# ecd5_target_db register map
Vendor: Texas Instruments
Address unit: 16 bits
Registers are 32-bit, access per field, reset 0x0 unless marked. A register's access mark holds for its fields unless they carry their own. Offsets are as the file gives them; [hi:lo] are bit positions; {n}, {i} and the like mark numbered series; 'fields as' and 'values as' point back to an identical list; <NAME> marks a mode.

## DSS (part 2 of 5) — ipxact12_to_ccs_generated
{0x4C+8i} __ALL___DRM_BUF_DMAGROUPID_BIN{i} (i=1..3) — DMA Group ID for bin stream {i} Note : Valid only in frame decoupled mode
  [5:0] ID rw — Group ID for VDMA transfer
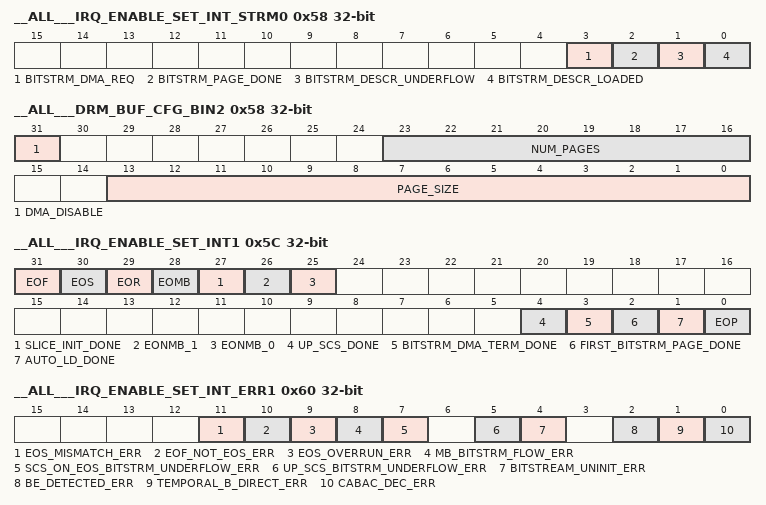
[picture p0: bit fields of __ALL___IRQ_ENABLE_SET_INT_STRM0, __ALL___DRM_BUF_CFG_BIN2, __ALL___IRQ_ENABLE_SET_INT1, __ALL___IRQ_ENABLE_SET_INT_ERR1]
0x58 __ALL___IRQ_ENABLE_SET_INT_STRM0 — Interrupt enable for each of the sources for interrupt INT_STRM0 Writing "1" to specific field in this register enables the corresponding source for interrupt generatation The read value reflects whether the corresponding source is enabled/disabled for interrupt generation The following is the behavior for read/write into each of the individual fields : Write 0: No action Write 1: Enable interrupt Read 0: Interrupt disabled (masked) Read 1: Interrupt enabled
  [3] BITSTRM_DMA_REQ rw — S/W interactive DMA request interrupt enable
  [2] BITSTRM_PAGE_DONE rw — Page of Bitstream DMA done interrupt enable.
  [1] BITSTRM_DESCR_UNDERFLOW rw — DDR/SL2 bitstream data descriptor underflow interrupt enable
  [0] BITSTRM_DESCR_LOADED rw — DDR/SL2 bitstream data descriptor loaded interrupt enable
0x58 __ALL___DRM_BUF_CFG_BIN2 — Buffer Parameters and configuration for bin stream 2 Note : Valid only in frame decoupled mode
  [31] DMA_DISABLE rw — If '1', disables the triggering of VDMA. Only the SL2 buffer management is activated.
  [23:16] NUM_PAGES rw — Number of pages in SL2
  [13:0] PAGE_SIZE rw — Size of each page in SL2 (in bytes); bits[3:0] are ignored, so the effective size is a multiple of 16 bytes Although the VDMA transfer for bin stream is deterministic, PAGE_SIZE is needed by ECD5 to know when to trigger VDMA - i.e. when the page becomes full. Since the size of each entry/write in the bin buffer is not fixed, the DMA is triggered when the total size of the wriiten data reaches PAGE_SIZE
0x5C __ALL___IRQ_ENABLE_SET_INT1 — Interrupt enable for each of the sources for interrupt INT1 Writing "1" to specific field in this register enables the corresponding source for interrupt generatation The read value reflects whether the corresponding source is enabled/disabled for interrupt generation The following is the behavior for read/write into each of the individual fields : Write 0: No action Write 1: Enable interrupt Read 0: Interrupt disabled (masked) Read 1: Interrupt enabled
  [31] EOF rw — End of Frame Interrupt enable
  [30] EOS rw — End of Slice Interrupt enable
  [29] EOR rw — End of Row Interrupt enable
  [28] EOMB rw — End of Macroblock Interrupt enable
  [27] SLICE_INIT_DONE rw — Slice init done interrupt enable
  [26] EONMB_1 rw — End of N Macroblock (i.e. counter 1 expired) interrupt enable.
  [25] EONMB_0 rw — End of N Macroblock (i.e. counter 0 expired) interrupt enable
  [4] UP_SCS_DONE rw — Unit processing startcode search interrupt enable.
  [3] BITSTRM_DMA_TERM_DONE rw — Bitstream DMA termination completed interrupt enable.
  [2] FIRST_BITSTRM_PAGE_DONE rw — First bitstream page DMA done interrupt enable
  [1] AUTO_LD_DONE rw — Auto Load Done Interrupt Enable
  [0] EOP rw — End of Pipe Interrupt enable
0x60 __ALL___IRQ_ENABLE_SET_INT_ERR1 — Interrupt enable for each of the sources for interrupt INT_ERR1 Writing "1" to specific field in this register enables the corresponding source for interrupt generatation The read value reflects whether the corresponding source is enabled/disabled for interrupt generation The following is the behavior for read/write into each of the individual fields : Write 0: No action Write 1: Enable interrupt Read 0: Interrupt disabled (masked) Read 1: Interrupt enabled
  [11] EOS_MISMATCH_ERR rw — End of slice mismatch error interrupt enable.
  [10] EOF_NOT_EOS_ERR rw — End of frame is not end of slice error interrupt enable
  [9] EOS_OVERRUN_ERR rw — End of slice overrun error interrupt enable
  [8] MB_BITSTRM_FLOW_ERR rw — Underflow in bitstream during MB decode error interrupt enable.
  [7] SCS_ON_EOS_BITSTRM_UNDERFLOW_ERR rw — Underflow in bitstream during startcode search after EOS error interrupt enable.
  [5] UP_SCS_BITSTRM_UNDERFLOW_ERR rw — Underflow in bitstream during startcode search unit processing.
  [4] BITSTREAM_UNINIT_ERR rw — Bitstream initialization without bitstream descriptor programmation error interrupt enable
  [2] BE_DETECTED_ERR rw — FE error due to error detected in BE interrupt enable.
  [1] TEMPORAL_B_DIRECT_ERR rw — Temporal B Direct Detected Error Interrupt Enable
  [0] CABAC_DEC_ERR rw — CABAC Decoder Error Interrupt Enable
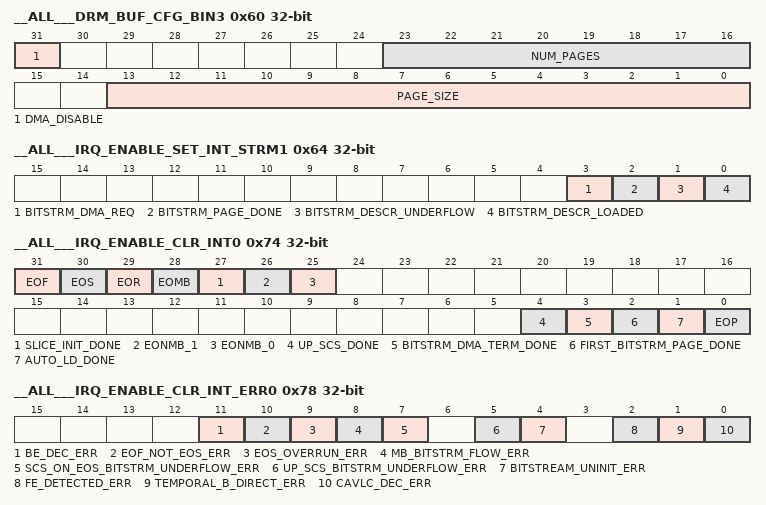
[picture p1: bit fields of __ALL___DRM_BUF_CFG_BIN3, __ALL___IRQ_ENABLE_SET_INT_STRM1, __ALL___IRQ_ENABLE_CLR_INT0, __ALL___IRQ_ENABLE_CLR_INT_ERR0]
0x60 __ALL___DRM_BUF_CFG_BIN3 — Buffer Parameters and configuration for bin stream 3 Note : Valid only in frame decoupled mode
  fields as __ALL___DRM_BUF_CFG_BIN2
0x64 __ALL___IRQ_ENABLE_SET_INT_STRM1 — Interrupt enable for each of the sources for interrupt INT_STRM1 Writing "1" to specific field in this register enables the corresponding source for interrupt generatation The read value reflects whether the corresponding source is enabled/disabled for interrupt generation The following is the behavior for read/write into each of the individual fields : Write 0: No action Write 1: Enable interrupt Read 0: Interrupt disabled (masked) Read 1: Interrupt enabled
  fields as __ALL___IRQ_ENABLE_SET_INT_STRM0
0x74 __ALL___IRQ_ENABLE_CLR_INT0 — Interrupt disable for each of the sources for interrupt INT0 Writing "1" to specific field in this register disables the corresponding source for interrupt generatation The read value reflects whether the corresponding source is enabled/disabled for interrupt generation The following is the behavior for read/write into each of the individual fields : Write 0: No action Write 1: Disable interrupt Read 0: Interrupt disabled (masked) Read 1: Interrupt enabled
  [31] EOF rw — End of Frame Interrupt disable
  [30] EOS rw — End of Slice Interrupt disable
  [29] EOR rw — End of Row Interrupt disable
  [28] EOMB rw — End of Macroblock Interrupt disable
  [27] SLICE_INIT_DONE rw — Slice init done interrupt disable
  [26] EONMB_1 rw — End of N Macroblock (i.e. counter 1 expired) interrupt disable
  [25] EONMB_0 rw — End of N Macroblock (i.e. counter 0 expired) interrupt disable
  [4] UP_SCS_DONE rw — Unit processing startcode search interrupt disable
  [3] BITSTRM_DMA_TERM_DONE rw — Bitstream DMA termination completed interrupt disable.
  [2] FIRST_BITSTRM_PAGE_DONE rw — First bitstream page DMA done interrupt disable
  [1] AUTO_LD_DONE rw — Auto Load Done Interrupt disable
  [0] EOP rw — End of Pipe Interrupt disable
0x78 __ALL___IRQ_ENABLE_CLR_INT_ERR0 — Interrupt disable for each of the sources for interrupt INT_ERR0 Writing "1" to specific field in this register disables the corresponding source for interrupt generatation The read value reflects whether the corresponding source is enabled/disabled for interrupt generation The following is the behavior for read/write into each of the individual fields : Write 0: No action Write 1: Disable interrupt Read 0: Interrupt disabled (masked) Read 1: Interrupt enabled
  [11] BE_DEC_ERR rw — BE Decoder Error interrupt disable
  [10] EOF_NOT_EOS_ERR rw — End of frame is not end of slice error interrupt disable
  [9] EOS_OVERRUN_ERR rw — End of slice overrun error interrupt disable
  [8] MB_BITSTRM_FLOW_ERR rw — Underflow/overflow in bitstream during MB decode/encode error interrupt disable.
  [7] SCS_ON_EOS_BITSTRM_UNDERFLOW_ERR rw — Underflow in bitstream during startcode search after EOS error interrupt disable.
  [5] UP_SCS_BITSTRM_UNDERFLOW_ERR rw — Underflow in bitstream during startcode search unit processing
  [4] BITSTREAM_UNINIT_ERR rw — Bitstream initialization without bitstream descriptor programmation error interrupt disable
  [2] FE_DETECTED_ERR rw — BE error due to error detected in FE interrupt disable.
  [1] TEMPORAL_B_DIRECT_ERR rw — Temporal B Direct Detected Error Interrupt disable
  [0] CAVLC_DEC_ERR rw — CAVLC Decoder Error Interrupt disable
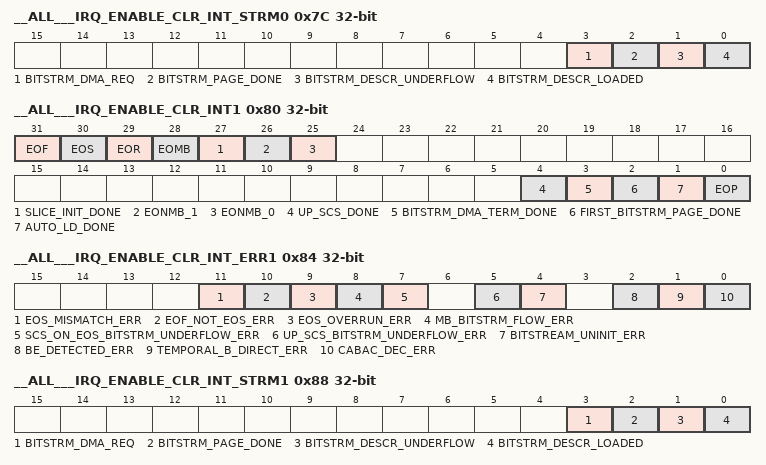
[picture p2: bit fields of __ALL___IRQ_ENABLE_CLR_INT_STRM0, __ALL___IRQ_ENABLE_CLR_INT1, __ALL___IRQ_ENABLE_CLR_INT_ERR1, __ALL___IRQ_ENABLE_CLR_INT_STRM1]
0x7C __ALL___IRQ_ENABLE_CLR_INT_STRM0 — Interrupt disable for each of the sources for interrupt INT_STRM0 Writing "1" to specific field in this register disables the corresponding source for interrupt generatation The read value reflects whether the corresponding source is enabled/disabled for interrupt generation The following is the behavior for read/write into each of the individual fields : Write 0: No action Write 1: Disable interrupt Read 0: Interrupt disabled (masked) Read 1: Interrupt enabled
  [3] BITSTRM_DMA_REQ rw — S/W interactive DMA request interrupt disable
  [2] BITSTRM_PAGE_DONE rw — Page of Bitstream DMA done interrupt disable
  [1] BITSTRM_DESCR_UNDERFLOW rw — DDR/SL2 bitstream data descriptor underflow interrupt disable
  [0] BITSTRM_DESCR_LOADED rw — DDR/SL2 bitstream data descriptor loaded interrupt disable
0x80 __ALL___IRQ_ENABLE_CLR_INT1 — Interrupt disable for each of the sources for interrupt INT1 Writing "1" to specific field in this register disables the corresponding source for interrupt generatation The read value reflects whether the corresponding source is enabled/disabled for interrupt generation The following is the behavior for read/write into each of the individual fields : Write 0: No action Write 1: Disable interrupt Read 0: Interrupt disabled (masked) Read 1: Interrupt enabled
  fields as __ALL___IRQ_ENABLE_CLR_INT0
0x84 __ALL___IRQ_ENABLE_CLR_INT_ERR1 — Interrupt disable for each of the sources for interrupt INT_ERR1 Writing "1" to specific field in this register disables the corresponding source for interrupt generatation The read value reflects whether the corresponding source is enabled/disabled for interrupt generation The following is the behavior for read/write into each of the individual fields : Write 0: No action Write 1: Disable interrupt Read 0: Interrupt disabled (masked) Read 1: Interrupt enabled
  [11] EOS_MISMATCH_ERR rw — End of slice mismatch error interrupt disable.
  [10] EOF_NOT_EOS_ERR rw — End of frame is not end of slice error interrupt disable
  [9] EOS_OVERRUN_ERR rw — End of slice overrun error interrupt enable
  [8] MB_BITSTRM_FLOW_ERR rw — Underflow in bitstream during MB decode error interrupt disable.
  [7] SCS_ON_EOS_BITSTRM_UNDERFLOW_ERR rw — Underflow in bitstream during startcode search after EOS error interrupt disable.
  [5] UP_SCS_BITSTRM_UNDERFLOW_ERR rw — Underflow in bitstream during startcode search unit processing.
  [4] BITSTREAM_UNINIT_ERR rw — Bitstream initialization without bitstream descriptor programmation error interrupt disable
  [2] BE_DETECTED_ERR rw — FE error due to error detected in BE interrupt disable.
  [1] TEMPORAL_B_DIRECT_ERR rw — Temporal B Direct Detected Error Interrupt disable
  [0] CABAC_DEC_ERR rw — CABAC Decoder Error Interrupt disable
0x88 __ALL___IRQ_ENABLE_CLR_INT_STRM1 — Interrupt disable for each of the sources for interrupt INT_STRM1 Writing "1" to specific field in this register disables the corresponding source for interrupt generatation The read value reflects whether the corresponding source is enabled/disabled for interrupt generation The following is the behavior for read/write into each of the individual fields : Write 0: No action Write 1: Disable interrupt Read 0: Interrupt disabled (masked) Read 1: Interrupt enabled
  fields as __ALL___IRQ_ENABLE_CLR_INT_STRM0
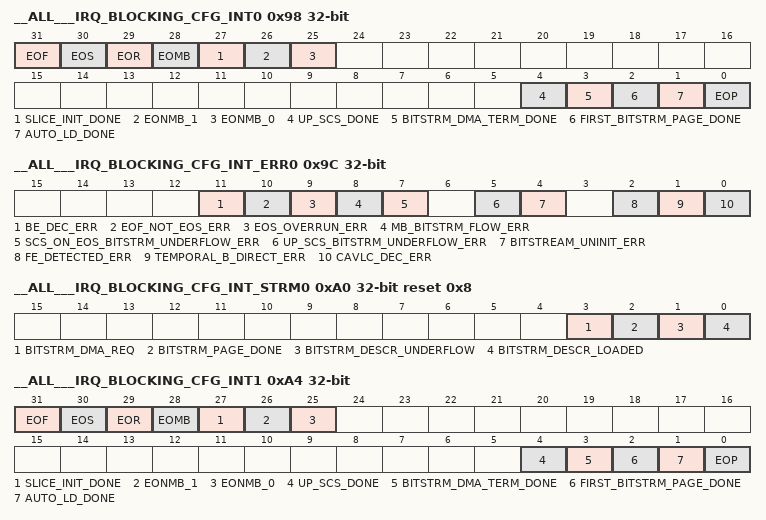
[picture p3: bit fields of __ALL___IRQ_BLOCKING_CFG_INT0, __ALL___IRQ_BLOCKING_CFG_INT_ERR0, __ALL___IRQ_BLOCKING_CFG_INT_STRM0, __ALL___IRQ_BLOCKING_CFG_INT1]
0x98 __ALL___IRQ_BLOCKING_CFG_INT0 — Interrupt blocking configuration for interrupt INT0 If a bit in this register is set to "1", the ECD5 halts after it generates an interrupt for the corresponding interrupt source, and waits for interrupt acknowledgement for that interrupt line before continuing execution. If a bit in this register is set to "0", the ECD5 does not halt after it generates an interrupt for the corresponding interrupt source The configuration in this register only apply to enabled interrupt sources Note : The halt on blocking interrupt is independent for FE and BE; i.e. if BE generates a blocking interrupt, only the BE is halted until ack is received; the FE continues processing.
  [31] EOF rw — End of Frame Interrupt blocking configuration
  [30] EOS rw — End of Slice Interrupt blocking configuration
  [29] EOR rw — End of Row Interrupt blocking configuration
  [28] EOMB rw — End of Macroblock Interrupt blocking configuration
  [27] SLICE_INIT_DONE rw — Slice init done interrupt blocking configuration
  [26] EONMB_1 rw — End of N Macroblock (i.e. counter 1 expired) interrupt blocking configuration
  [25] EONMB_0 rw — End of N Macroblock (i.e. counter 0 expired) interrupt blocking configuration
  [4] UP_SCS_DONE rw — Unit processing startcode search interrupt blocking configuration
  [3] BITSTRM_DMA_TERM_DONE rw — Bitstream DMA termination completed interrupt blocking configuration.
  [2] FIRST_BITSTRM_PAGE_DONE rw — First bitstream page DMA done interrupt blocking configuration
  [1] AUTO_LD_DONE rw — Auto Load Done Interrupt blocking configuration
  [0] EOP rw — End of Pipe Interrupt blocking configuration
0x9C __ALL___IRQ_BLOCKING_CFG_INT_ERR0 — Interrupt blocking configuration for interrupt INT_ERR0 If a bit in this register is set to "1", the ECD5 halts after it generates an interrupt for the corresponding interrupt source, and waits for interrupt acknowledgement for that interrupt line before continuing execution. If a bit in this register is set to "0", the ECD5 does not halt after it generates an interrupt for the corresponding interrupt source The configuration in this register only apply to enabled interrupt sources Note : The halt on blocking interrupt is independent for FE and BE; i.e. if BE generates a blocking interrupt, only the BE is halted until ack is received; the FE continues processing.
  [11] BE_DEC_ERR rw — BE Decoder Error interrupt blocking configuration
  [10] EOF_NOT_EOS_ERR rw — End of frame is not end of slice error interrupt blocking configuration
  [9] EOS_OVERRUN_ERR rw — End of slice overrun error interrupt blocking configuration
  [8] MB_BITSTRM_FLOW_ERR rw — Underflow/overflow in bitstream during MB decode/encode error interrupt blocking configuration.
  [7] SCS_ON_EOS_BITSTRM_UNDERFLOW_ERR rw — Underflow in bitstream during startcode search after EOS error interrupt blocking configuration.
  [5] UP_SCS_BITSTRM_UNDERFLOW_ERR rw — Underflow in bitstream during startcode search unit processing interrupt blocking configuration.
  [4] BITSTREAM_UNINIT_ERR rw — Bitstream initialization without bitstream descriptor programmation error interrupt blocking configuration.
  [2] FE_DETECTED_ERR rw — BE error due to error detected in FE interrupt blocking configuration.
  [1] TEMPORAL_B_DIRECT_ERR rw — Temporal B Direct Detected Error interrupt blocking configuration
  [0] CAVLC_DEC_ERR rw — CAVLC Decoder Error interrupt blocking configuration
0xA0 __ALL___IRQ_BLOCKING_CFG_INT_STRM0 reset 0x8 — Interrupt blocking configuration for interrupt INT_STRM0 If a bit in this register is set to "1", the ECD5 halts after it generates an interrupt for the corresponding interrupt source, and waits for interrupt acknowledgement for that interrupt line before continuing execution. If a bit in this register is set to "0", the ECD5 does not halt after it generates an interrupt for the corresponding interrupt source The configuration in this register only apply to enabled interrupt sources Note : The halt on blocking interrupt is independent for FE and BE; i.e. if BE generates a blocking interrupt, only the BE is halted until ack is received; the FE continues processing.
  [3] BITSTRM_DMA_REQ ro — S/W interactive DMA request interrupt blocking configuration. This interrupt is always blocking.
  [2] BITSTRM_PAGE_DONE rw — Page of Bitstream DMA done interrupt blocking configuration
  [1] BITSTRM_DESCR_UNDERFLOW rw — DDR/SL2 bitstream data descriptor underflow interrupt blocking configuration
  [0] BITSTRM_DESCR_LOADED rw — DDR/SL2 bitstream data descriptor loaded interrupt blocking configuration
0xA4 __ALL___IRQ_BLOCKING_CFG_INT1 — Interrupt blocking configuration for interrupt INT1 If a bit in this register is set to "1", the ECD5 halts after it generates an interrupt for the corresponding interrupt source, and waits for interrupt acknowledgement for that interrupt line before continuing execution. If a bit in this register is set to "0", the ECD5 does not halt after it generates an interrupt for the corresponding interrupt source The configuration in this register only apply to enabled interrupt sources Note : The halt on blocking interrupt is independent for FE and BE; i.e. if BE generates a blocking interrupt, only the BE is halted until ack is received; the FE continues processing.
  [31] EOF rw — End of Frame interrupt blocking configuration
  [30] EOS rw — End of Slice interrupt blocking configuration
  [29] EOR rw — End of Row interrupt blocking configuration
  [28] EOMB rw — End of Macroblock interrupt blocking configuration
  [27] SLICE_INIT_DONE rw — Slice init done interrupt blocking configuration
  [26] EONMB_1 rw — End of N Macroblock (i.e. counter 1 expired) interrupt blocking configuration
  [25] EONMB_0 rw — End of N Macroblock (i.e. counter 0 expired) interrupt blocking configuration
  [4] UP_SCS_DONE rw — Unit processing startcode search interrupt blocking configuration
  [3] BITSTRM_DMA_TERM_DONE rw — Bitstream DMA termination completed interrupt blocking configuration.
  [2] FIRST_BITSTRM_PAGE_DONE rw — First bitstream page DMA done interrupt blocking configuration
  [1] AUTO_LD_DONE rw — Auto Load Done interrupt blocking configuration
  [0] EOP rw — End of Pipe interrupt blocking configuration
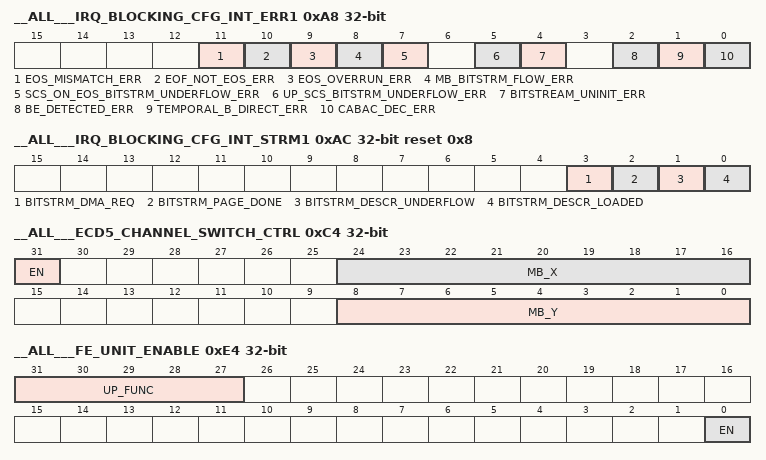
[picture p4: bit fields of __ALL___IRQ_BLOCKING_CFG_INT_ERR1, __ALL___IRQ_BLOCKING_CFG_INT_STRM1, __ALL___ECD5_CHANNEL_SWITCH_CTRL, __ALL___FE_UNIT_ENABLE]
0xA8 __ALL___IRQ_BLOCKING_CFG_INT_ERR1 — Interrupt blocking configuration for interrupt INT_ERR1 If a bit in this register is set to "1", the ECD5 halts after it generates an interrupt for the corresponding interrupt source, and waits for interrupt acknowledgement for that interrupt line before continuing execution. If a bit in this register is set to "0", the ECD5 does not halt after it generates an interrupt for the corresponding interrupt source The configuration in this register only apply to enabled interrupt sources Note : The halt on blocking interrupt is independent for FE and BE; i.e. if BE generates a blocking interrupt, only the BE is halted until ack is received; the FE continues processing.
  [11] EOS_MISMATCH_ERR rw — End of slice mismatch error interrupt blocking configuration.
  [10] EOF_NOT_EOS_ERR rw — End of frame is not end of slice error interrupt blocking configuration
  [9] EOS_OVERRUN_ERR rw — End of slice overrun error interrupt enable
  [8] MB_BITSTRM_FLOW_ERR rw — Underflow in bitstream during MB decode error interrupt blocking configuration.
  [7] SCS_ON_EOS_BITSTRM_UNDERFLOW_ERR rw — Underflow in bitstream during startcode search after EOS error interrupt blocking configuration.
  [5] UP_SCS_BITSTRM_UNDERFLOW_ERR rw — Underflow in bitstream during startcode search unit processing interrupt blocking configuration.
  [4] BITSTREAM_UNINIT_ERR rw — Bitstream initialization without bitstream descriptor programmation error interrupt blocking configuration.
  [2] BE_DETECTED_ERR rw — FE error due to error detected in BE interrupt blocking configuration.
  [1] TEMPORAL_B_DIRECT_ERR rw — Temporal B Direct Detected Error interrupt blocking configuration
  [0] CABAC_DEC_ERR rw — CABAC Decoder Error interrupt blocking configuration
0xAC __ALL___IRQ_BLOCKING_CFG_INT_STRM1 reset 0x8 — Interrupt blocking configuration for interrupt INT_STRM1 If a bit in this register is set to "1", the ECD5 halts after it generates an interrupt for the corresponding interrupt source, and waits for interrupt acknowledgement for that interrupt line before continuing execution. If a bit in this register is set to "0", the ECD5 does not halt after it generates an interrupt for the corresponding interrupt source The configuration in this register only apply to enabled interrupt sources Note : The halt on blocking interrupt is independent for FE and BE; i.e. if BE generates a blocking interrupt, only the BE is halted until ack is received; the FE continues processing.
  fields as __ALL___IRQ_BLOCKING_CFG_INT_STRM0
0xC0 __ALL___ECD5_COMMON_CFG — ECD5 Common configuration - common for FE and BE
  [0] CABAC_FRAME_DECOUPLING_EN rw — Specifies if frame level decoupling is enabled for CABAC 0 - No frame level decoupling 1 - Frame level decoupling enabled
0xC4 __ALL___ECD5_CHANNEL_SWITCH_CTRL — ECD5 Channel switching control This register controls the channel switching behaviour of ECD5. This register is used for both FE and BE switching. This register is used only in decode mode (since in encode, the ECD5 is not the head of the pipe) Note : Channel switching has to be disabled in frame decoupling mode (ECD5_COMMON_CFG.CABAC_FRAME_DECOUPLING_EN = 1), since channel switching is not specified in this mode
  [31] EN rw — Specifies if channel switching is enabled 0 - Disabled; 1 - Enabled
  [24:16] MB_X rw — Specifies the X position in the frame, of the MB, after which, switching happens , i.e. end of pipe will be asserted on reaching end of slice
  [8:0] MB_Y rw — Specifies the Y position in the frame, of the MB, after which, switching happens , i.e. end of pipe will be asserted on reaching end of slice
0xC8 __ALL___ECD5_ICONT_INTF_CTRL — ECD5 Control for direct bitstream communication interface with iCont
  [0] EN rw — Specifies if direct bitstream communication interface with iCont is enabled 0 - Disable interface 1 - Enable interface
0xCC __ALL___ECD5_BIN_SBC_CFG reset 0x1 — ECD5 Bin SBC configuration
  [0] WORD_MODE_BYPASS_EN rw — If 1, enables the bypass mode for all the bin SBCs in word mode; debug only
0xE0 __ALL___FE_ENABLE — FE Enable
  [0] EN rw — Setting this bit enables the FE Engine. This bit is cleared on end of frame/sub-frame.
0xE4 __ALL___FE_UNIT_ENABLE — FE Unit Enable
  [31:27] UP_FUNC rw — Specifies the function to trigger in unit processing mode (MODE == 0). Irrelevant in frame mode (MODE == 1) 0x00 - Slice Data Processing 0x01 - Startcode Search 0x02 - Bitstream DMA Initialization 0x03 - Bitstream DMA termination 0x04 - End of Pipe Processing Other values are unsupported
  [0] EN rw — Setting this bit triggers the selected engine/flow. For slice data processing, this bit needs to be set to trigger the slice data processing flow, after the slice header decoding is complete. This bit is cleared on completion of the selected engine/flow processing. Writing '0' is ignored. Setting to '1' while already set is also ignored. The bit should be set only when it is '0', i.e. no processing function is currently active
0xE8 __ALL___FE_MB_ENABLE — FE MB Enable
  [0] EN rw — Triggers the FE MB processing engine, when MB level control is enabled (FUNC_MMR.FE_L1_CFG_0.SDP_MB_MODE == 1 ) This bit is cleared on completion of MB processing
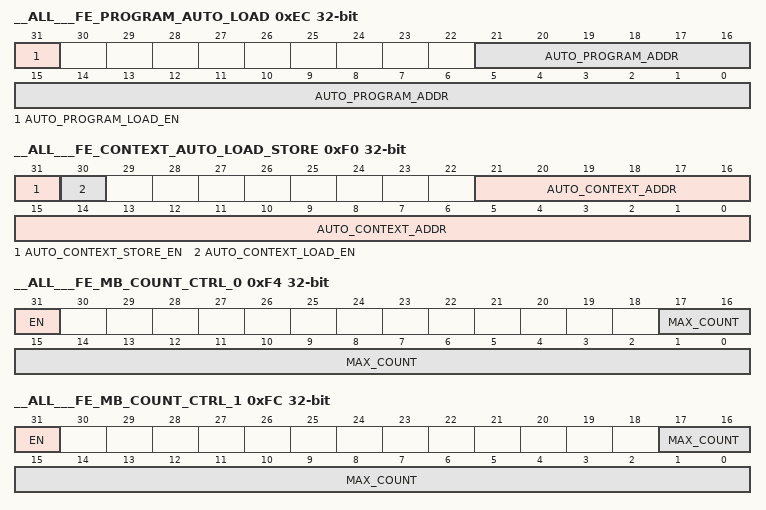
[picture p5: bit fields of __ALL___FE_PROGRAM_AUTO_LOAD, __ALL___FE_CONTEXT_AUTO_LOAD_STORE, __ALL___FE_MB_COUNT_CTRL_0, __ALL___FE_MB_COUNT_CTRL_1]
0xEC __ALL___FE_PROGRAM_AUTO_LOAD — Enable and SL2 location of the Auto Load MMR Image
  [31] AUTO_PROGRAM_LOAD_EN rw — 1 => Program Auto Load Enabled
  [21:0] AUTO_PROGRAM_ADDR rw — Program Auto Load SL2 Base Address; the last 4 bits are ignored and are assumed 0
0xF0 __ALL___FE_CONTEXT_AUTO_LOAD_STORE — Enable and SL2 location of the Context MMR Image Note : Currently unused; reserved for future use.
  [31] AUTO_CONTEXT_STORE_EN rw — 1 => Context Auto Store Enabled
  [30] AUTO_CONTEXT_LOAD_EN rw — 1 => Context Auto Load Enabled
  [21:0] AUTO_CONTEXT_ADDR rw — Context Auto Load / Store SL2 Base Address
0xF4 __ALL___FE_MB_COUNT_CTRL_0 — Control for FE N-MB Interrupt 0
  [31] EN rw — Enable/disable counter to generate FE N-MB interrupt 0
  [17:0] MAX_COUNT rw — Number of MBs, after which FE N-MB interrupt 0 needs to be generated. If 1, interrupt generated every MB. MAX_COUNT of 0 is illegal; EN bit should be 0 if MAX_COUNT = 0.
0xF8 __ALL___FE_MB_COUNTER_0 — Count of number of MBs completed, for controlling FE N-MB interrupt 0
  [17:0] COUNTER rw — If FE_MB_COUNT_CTRL_0.EN == 1, this field is incremented, and then compared against FE_MB_COUNT_CTRL_0.MAX_COUNT, for each MB executed. If compare matches (and FE_MB_COUNT_CTRL_0.EN == 1 ), FE N-MB interrupt 0 is generated (if the interrupt is enabled), and the field is reset to 0.
0xFC __ALL___FE_MB_COUNT_CTRL_1 — Control for FE N-MB Interrupt 1
  [31] EN rw — Enable/disable counter to generate FE N-MB interrupt 1
  [17:0] MAX_COUNT rw — Number of MBs, after which FE N-MB interrupt 1 needs to be generated. If 1, interrupt generated every MB. MAX_COUNT of 0 is illegal; EN bit should be 0 if MAX_COUNT = 0.
0x100 __ALL___FE_MB_COUNTER_1 — Count of number of MBs completed, for controlling FE N-MB interrupt 1
  [17:0] COUNTER rw — If FE_MB_COUNT_CTRL_1.EN == 1, this field is incremented, and then compared against FE_MB_COUNT_CTRL_1.MAX_COUNT, for each MB executed. If compare matches ( and FE_MB_COUNT_CTRL_1.EN == 1 ), FE N-MB interrupt 1 is generated (if the interrupt is enabled), and the field is reset to 0.
0x120 __ALL___BE_ENABLE — BE Enable
  [0] EN rw — Setting this bit enables the BE Engine. This bit is cleared on end of frame/sub-frame.
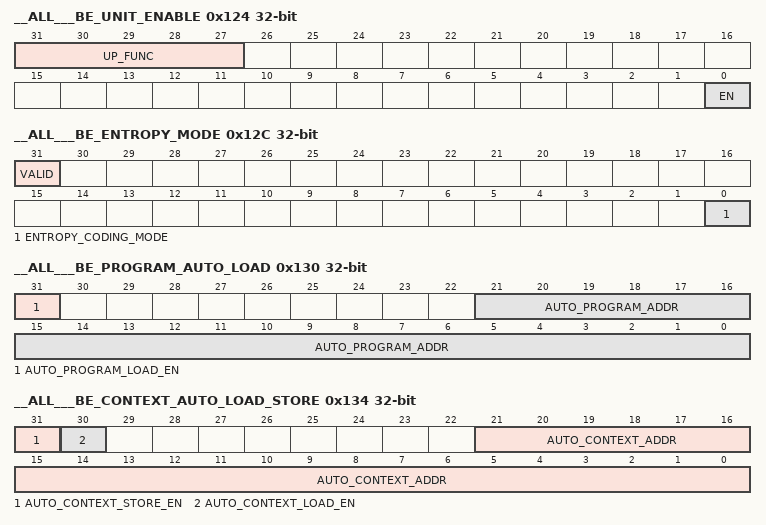
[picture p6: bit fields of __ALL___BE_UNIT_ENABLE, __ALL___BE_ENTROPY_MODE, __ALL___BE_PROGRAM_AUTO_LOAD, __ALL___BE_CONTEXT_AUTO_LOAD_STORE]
0x124 __ALL___BE_UNIT_ENABLE — BE Unit Enable This register is valid only in encode and CAVLC decode. It is unused in CABAC decode.
  [31:27] UP_FUNC rw — Specifies the function to trigger for encode and CAVLC decode. 0x00 - Slice Data Processing 0x01 - Startcode Search 0x02 - Bitstream DMA initialization 0x03 - Bitstream DMA termination 0x04 - End of Pipe Processing Other values are unsupported
  [0] EN rw — Setting this bit triggers the selected engine/flow. For slice data processing, this bit needs to be set to trigger the slice data processing flow, after the slice header decoding is complete. This bit is cleared on completion of the selected engine/flow processing. Writing '0' is ignored. Setting to '1' while already set is also ignored. The bit should be set only when it is '0', i.e. no processing function is currently active
0x128 __ALL___BE_MB_ENABLE — BE MB Enable
  [0] EN rw — Triggers the BE MB processing engine, when MB level control is enabled (FUNC_MMR.BE_L1_CFG_0.SDP_MB_MODE == 1 ) This bit is cleared on completion of MB processing
0x12C __ALL___BE_ENTROPY_MODE — BE Entropy Coding mode
  [31] VALID rw — 1 => The entropy mode setting is valid 0 => The entropy coding mode is not valid The ECD5 BE logic waits until this bit is set, before it starts the actual processing of data.
  [0] ENTROPY_CODING_MODE rw — Specifies the entropy coding scheme for the BE logic 0 - CAVLC 1 - CABAC
0x130 __ALL___BE_PROGRAM_AUTO_LOAD — Enable and SL2 location of the Auto Load MMR Image
  [31] AUTO_PROGRAM_LOAD_EN rw — 1 => Program Auto Load Enabled
  [21:0] AUTO_PROGRAM_ADDR rw — Program Auto Load SL2 Base Address
0x134 __ALL___BE_CONTEXT_AUTO_LOAD_STORE — Enable and SL2 location of the Context MMR Image Note : Currently unused; reserved for future use.
  fields as __ALL___FE_CONTEXT_AUTO_LOAD_STORE
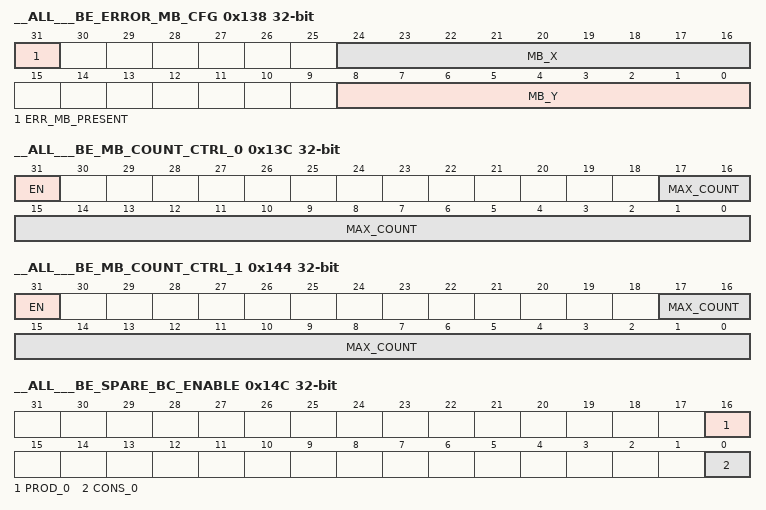
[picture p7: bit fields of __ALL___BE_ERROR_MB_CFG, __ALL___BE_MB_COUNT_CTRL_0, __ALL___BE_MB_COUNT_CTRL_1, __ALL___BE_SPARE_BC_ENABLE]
0x138 __ALL___BE_ERROR_MB_CFG — ECD5 BE Error MB configuration This register is to be written by SW only in frame decoupled mode for CABAC decode in the BE. This register specifies if an erroneous MB was decoded in the FE in the current frame (when it was decoded earlier in the FE), and if so the address of the next MB that has the error. In non-frame decoupled mode and in CABAC decode, this register is set by the FE H/W to indicate to the BE if an error was detected by the FE, and the MB in which the error was detected.
  [31] ERR_MB_PRESENT rw — Specifies if an erroneous MB is present in the current frame, in the future, from the current point of decoding. If there is no other MB that is erroneous in the current frame, this bit will have to be reset, before re-enabling the BE after the previous error. This bit should be written by SW only in the frame decoupled configuration, and when the BE is triggered for CABAC decoding. In non-frame decoupled mode CABAC decode, this bit will be set by the H/W if an error is detected by the FE.
  [24:16] MB_X rw — Specifies the X position of the next MB that is erroneous (detected to be in error by the FE) in the current frame
  [8:0] MB_Y rw — Specifies the Y position of the next MB that is erroneous (detected to be in error by the FE) in the current frame
0x13C __ALL___BE_MB_COUNT_CTRL_0 — Control forBFE N-MB Interrupt 0
  [31] EN rw — Enable/disable counter to generate BE N-MB interrupt 0
  [17:0] MAX_COUNT rw — Number of MBs, after which BE N-MB interrupt 0 needs to be generated. If 1, interrupt generated every MB. MAX_COUNT of 0 is illegal; EN bit should be 0 if MAX_COUNT = 0.
0x140 __ALL___BE_MB_COUNTER_0 — Count of number of MBs completed, for controlling BE N-MB interrupt 0
  [17:0] COUNTER rw — If BE_MB_COUNT_CTRL_0.EN == 1, this field is incremented, and then compared against BE_MB_COUNT_CTRL_0.MAX_COUNT, for each MB executed. If compare matches ( and BE_MB_COUNT_CTRL_0.EN == 1 ), BE N-MB interrupt 0 is generated (if the interrupt is enabled), and the field is reset to 0.
0x144 __ALL___BE_MB_COUNT_CTRL_1 — Control for BE N-MB Interrupt 1
  [31] EN rw — Enable/disable counter to generate BE N-MB interrupt 1
  [17:0] MAX_COUNT rw — Number of MBs, after which BE N-MB interrupt 1 needs to be generated. If 1, interrupt generated every MB. MAX_COUNT of 0 is illegal; EN bit should be 0 if MAX_COUNT = 0.
0x148 __ALL___BE_MB_COUNTER_1 — Count of number of MBs completed, for controlling BE N-MB interrupt 1
  [17:0] COUNTER rw — If BE_MB_COUNT_CTRL_1.EN == 1, this field is incremented, and then compared against BE_MB_COUNT_CTRL_1.MAX_COUNT, for each MB executed. If compare matches ( and BE_MB_COUNT_CTRL_1.EN == 1 ), BE N-MB interrupt 1 is generated (if the interrupt is enabled), and the field is reset to 0.
0x14C __ALL___BE_SPARE_BC_ENABLE — Enable for dependency on spare BCs
  [16] PROD_0 rw — 1 - Enable dependency on spare producer SL2BC
  [0] CONS_0 rw — 1 - Enable dependency on spare consumer SL2BC
0x160 __ALL___FE_BC_CLEAR — BC Clear Register for FE in frame decoupled mode Setting a bit initializes the corresponding BC (if buffer controller present) and/or the corresponding BC write interface (if present) The bits are auto-cleared
  [31] SLICEINFO_BC_CLEAR wo — BC Clear for sliceInfo BC; Setting this bit to "1" - Initializes the input sliceInfo BC
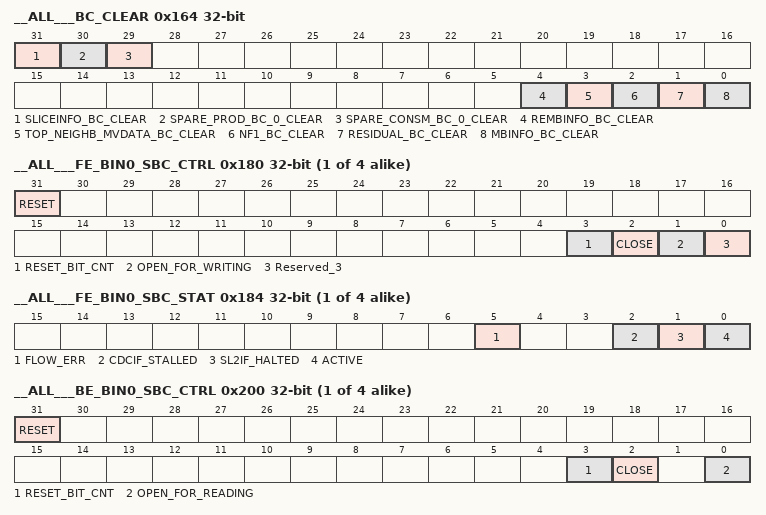
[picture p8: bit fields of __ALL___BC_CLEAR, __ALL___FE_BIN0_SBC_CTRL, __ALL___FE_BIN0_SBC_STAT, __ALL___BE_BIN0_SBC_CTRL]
0x164 __ALL___BC_CLEAR — BC Clear Register Setting a bit initializes the corresponding BC (if buffer controller present) and/or the corresponding BC write interface (if present) The bits are auto-cleared
  [31] SLICEINFO_BC_CLEAR wo — BC Clear for sliceInfo BC; Setting this bit to "1" - Initializes the input sliceInfo BC - Initializes the output sliceInfo BC interface - Initializes the internal sliceInfo BC between FE and BE
  [30] SPARE_PROD_BC_0_CLEAR wo — BC Clear for iCONT BC# 0; Setting this bit to "1" - Initializes the input spare BC #0
  [29] SPARE_CONSM_BC_0_CLEAR wo — BC Clear for iCONT BC#; Setting this bit to "1" - Initializes the input spare BC #1
  [4] REMBINFO_BC_CLEAR wo — BC Clear for refLayer ECd MBInfo BC; Setting this bit to "1" - Initializes the input interLayerInfo BC
  [3] TOP_NEIGHB_MVDATA_BC_CLEAR wo — BC Clear for Top_Neighb_MVData BC; Setting this bit to "1" - Initializes the output Top_Neighb_MVData BC interface
  [2] NF1_BC_CLEAR wo — BC Clear for NearNeighbourFlag BC; Setting this bit to "1" - Initializes the output NF1 BC interface
  [1] RESIDUAL_BC_CLEAR wo — BC Clear for Residual BC; Setting this bit to "1" - Initializes the input residual BC - Initializes the output residual BC interface
  [0] MBINFO_BC_CLEAR wo — BC Clear for MBInfo BC; Setting this bit to "1" - Initializes the input MBInfo BC - Initializes the output MBInfo top BC interface - Initializes the output MBInfo bottom BC interface - Initializes the internal MB level BC between FE and BE
{0x180+0x20*i} __ALL___FE_BIN{i}_SBC_CTRL (i=0..3) — FE Bin stream {i} SBC Control
  [31] RESET rw — Writing "1" resets SBC; for debug only
  [3] RESET_BIT_CNT rw — Writing "1" resets the bit counters in SBC; resets SBC_TOTAL_COUNT to 0; also resets internal counters; cleared in the next cycle.
  [2] CLOSE rw — Writing "1" closes SBC; automatically cleared on close completion
  [1] OPEN_FOR_WRITING rw — Writing "1" opens SBC for writing; automatically cleared on open completion
  [0] Reserved_3 ro — Writing "1" opens SBC for reading; automatically cleared on open completion
{0x184+0x20*i} __ALL___FE_BIN{i}_SBC_STAT ro (i=0..3) — FE Bin stream {i} SBC Status
  [5] FLOW_ERR — If 1, indicates that an overflow error is seen; cleared on open completion.
  [2] CDCIF_STALLED — If 1, indicates that codec i/f of SBC is stalled (not ready), due to lack of data in the internal registers of the SBC; valid after open; cleared on codec i/f becoming unstalled.
  [1] SL2IF_HALTED — If 1, indicates that the SL2 i/f of SBC is halted, due to lack of bitstream data in the SL2; valid after open; cleared when SL2 i/f is unhalted
  [0] ACTIVE — If 1, indicates that SBC is active - can be in read/write or halted state; valid after open; cleared on close
{0x188+0x20*i} __ALL___FE_BIN{i}_SBC_PTR (i=0..3) — FE Bin stream {i} SBC SL2 pointer
  [2:0] BIT_PTR rw — Next bit position in the byte at BYTEPTR. The following constraint applies : 0 <= BITPTR <= 7
{0x18C+0x20*i} __ALL___FE_BIN{i}_SBC_TOTAL_COUNT (i=0..3) — FE Bin stream {i} Number of bins written by the codec
  [26:0] CNT rw — Total bits written by the codec; this register can be written w/ initial value before the SBC is opened
{0x200+0x20*i} __ALL___BE_BIN{i}_SBC_CTRL (i=0..3) — BE Bin stream {i} SBC Control
  [31] RESET rw — Writing "1" resets SBC; for debug only
  [3] RESET_BIT_CNT rw — Writing "1" resets the bit counters in SBC; resets SBC_TOTAL_COUNT to 0; also resets internal counters; cleared in the next cycle.
  [2] CLOSE rw — Writing "1" closes SBC; automatically cleared on close completion
  [0] OPEN_FOR_READING rw — Writing "1" opens SBC for reading; automatically cleared on open completion
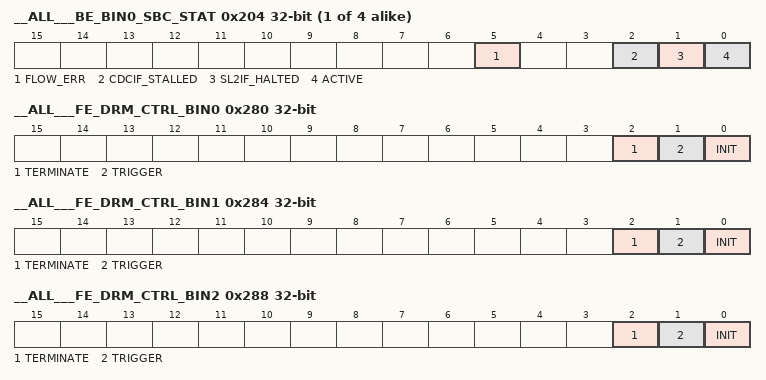
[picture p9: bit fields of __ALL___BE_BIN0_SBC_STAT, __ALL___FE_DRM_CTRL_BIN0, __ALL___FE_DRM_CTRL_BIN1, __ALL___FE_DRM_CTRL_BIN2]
{0x204+0x20*i} __ALL___BE_BIN{i}_SBC_STAT ro (i=0..3) — BE Bin stream {i} SBC Status
  [5] FLOW_ERR — If 1, indicates that an underflowerror is seen; cleared on open completion.
  [2] CDCIF_STALLED — If 1, indicates that codec i/f of SBC is stalled (not ready), due to lack of data in the internal registers of the SBC; valid after open; cleared on codec i/f becoming unstalled.
  [1] SL2IF_HALTED — If 1, indicates that the SL2 i/f of SBC is halted, due to lack of bitstream data in the SL2; valid after open; cleared when SL2 i/f is unhalted
  [0] ACTIVE — If 1, indicates that SBC is active - can be in read/write or halted state; valid after open; cleared on close
{0x208+0x20*i} __ALL___BE_BIN{i}_SBC_PTR (i=0..3) — BE Bin stream {i} SBC SL2 pointer
  fields as __ALL___FE_BIN0_SBC_PTR
{0x20C+0x20*i} __ALL___BE_BIN{i}_SBC_TOTAL_COUNT (i=0..3) — BE Bin stream {i} Number of bins read by the codec
  [26:0] CNT rw — Total bits read by the codec; this register can be written w/ initial value before the SBC is opened
0x280 __ALL___FE_DRM_CTRL_BIN0 — DRM Control for bin stream 0 in FE Note : Valid only in frame decoupled mode
  [2] TERMINATE rw — Debug only. Terminate DMA transfers; if set, then all in-progress and pending DMA is completed.
  [1] TRIGGER rw — Debug only. SW trigger; used to indicate availability of at least 1 empty page in the buffer.
  [0] INIT rw — Debug only. Initializes the DRM channel control FSM
0x284 __ALL___FE_DRM_CTRL_BIN1 — DRM Control for bin stream 1in FE Note : Valid only in frame decoupled mode
  fields as __ALL___FE_DRM_CTRL_BIN0
0x288 __ALL___FE_DRM_CTRL_BIN2 — DRM Control for bin stream 2 in FE Note : Valid only in frame decoupled mode
  fields as __ALL___FE_DRM_CTRL_BIN0
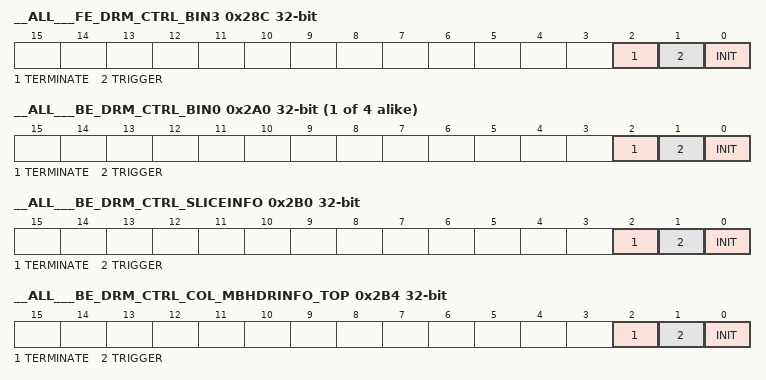
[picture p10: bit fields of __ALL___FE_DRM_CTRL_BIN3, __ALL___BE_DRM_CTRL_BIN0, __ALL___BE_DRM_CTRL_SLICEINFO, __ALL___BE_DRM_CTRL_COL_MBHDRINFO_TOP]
0x28C __ALL___FE_DRM_CTRL_BIN3 — DRM Control for bin stream 3 in FE Note : Valid only in frame decoupled mode
  fields as __ALL___FE_DRM_CTRL_BIN0
{0x2A0+4i} __ALL___BE_DRM_CTRL_BIN{i} (i=0..3) — DRM Control for bin stream {i} in BE Note : Valid only in frame decoupled mode
  fields as __ALL___FE_DRM_CTRL_BIN0
0x2B0 __ALL___BE_DRM_CTRL_SLICEINFO — DRM Control for sliceInfo Note : Valid only in frame decoupled mode
  [2] TERMINATE rw — Debug only. Terminate DMA transfers; if set, then any in-progress DMA is completed, and any pending DMA is discarded.
  [1] TRIGGER rw — Debug only. SW trigger; used to indicate fill of 1 page in the buffer.
  [0] INIT rw — Debug only. Initializes the DRM channel control FSM
0x2B4 __ALL___BE_DRM_CTRL_COL_MBHDRINFO_TOP — DRM Control for colocated top MBHdrInfo Note : Valid only in decode
  fields as __ALL___BE_DRM_CTRL_SLICEINFO
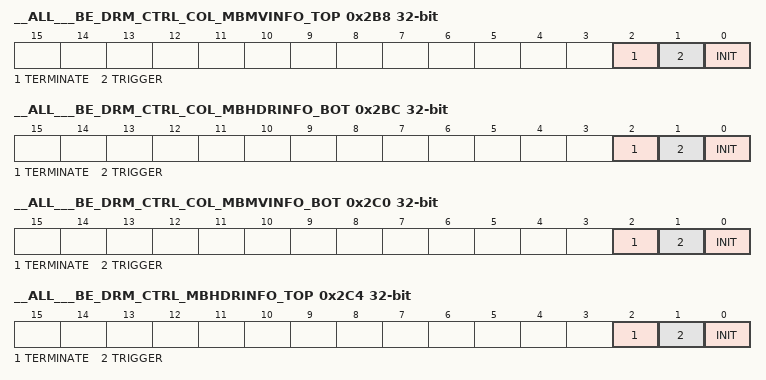
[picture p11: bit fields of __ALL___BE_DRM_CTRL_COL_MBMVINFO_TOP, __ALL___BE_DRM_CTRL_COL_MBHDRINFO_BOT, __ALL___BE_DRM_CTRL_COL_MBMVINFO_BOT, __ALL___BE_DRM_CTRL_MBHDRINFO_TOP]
0x2B8 __ALL___BE_DRM_CTRL_COL_MBMVINFO_TOP — DRM Control for colocated top MBMVInfo Note : Valid only in decode
  fields as __ALL___BE_DRM_CTRL_SLICEINFO
0x2BC __ALL___BE_DRM_CTRL_COL_MBHDRINFO_BOT — DRM Control for colocated bottom MBHdrInfo Note : Valid only in decode
  fields as __ALL___BE_DRM_CTRL_SLICEINFO
0x2C0 __ALL___BE_DRM_CTRL_COL_MBMVINFO_BOT — DRM Control for colocated bottom MBMVInfo Note : Valid only in decode
  fields as __ALL___BE_DRM_CTRL_SLICEINFO
0x2C4 __ALL___BE_DRM_CTRL_MBHDRINFO_TOP — DRM Control for current top MBHdrInfo Note : Valid only in decode
  fields as __ALL___BE_DRM_CTRL_SLICEINFO
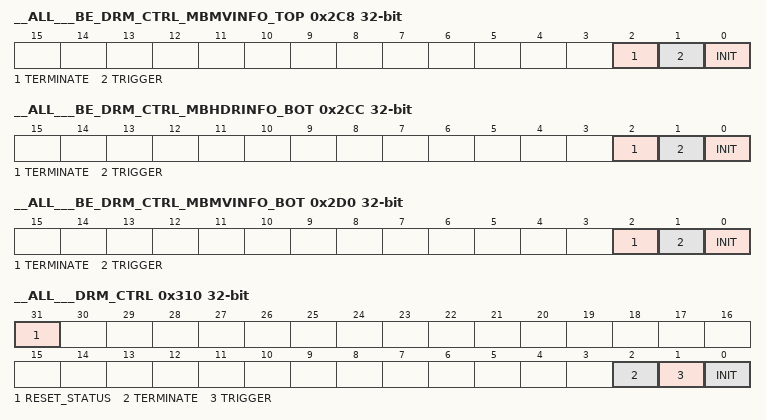
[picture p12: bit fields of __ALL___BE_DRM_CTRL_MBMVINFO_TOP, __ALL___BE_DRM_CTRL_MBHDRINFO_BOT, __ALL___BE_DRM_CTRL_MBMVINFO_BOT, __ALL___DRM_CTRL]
0x2C8 __ALL___BE_DRM_CTRL_MBMVINFO_TOP — DRM Control for current top MBMVInfo Note : Valid only in decode
  fields as __ALL___BE_DRM_CTRL_SLICEINFO
0x2CC __ALL___BE_DRM_CTRL_MBHDRINFO_BOT — DRM Control for current bottom MBHdrInfo Note : Valid only in decode
  fields as __ALL___BE_DRM_CTRL_SLICEINFO
0x2D0 __ALL___BE_DRM_CTRL_MBMVINFO_BOT — DRM Control for current bottom MBMVInfo Note : Valid only in decode
  fields as __ALL___BE_DRM_CTRL_SLICEINFO
0x310 __ALL___DRM_CTRL — DRM Control for bitstream
  [31] RESET_STATUS rw — Reset the status bits in DDR_BITSTRM_SHADOW_STATUS and SL2_BITSTRM_SHADOW_STATUS. Cleared in the next cycle.
  [2] TERMINATE rw — Debug only. Terminate DMA transfers; if set, then the following actions take place - All in-flight DMA is completed - If DMA direction is from DDR to SL2, all pending DMA requests are discarded - Status bits in DDR_BITSTRM_SHADOW_STATUS register are reset
  [1] TRIGGER rw — SW trigger; used to indicate consumption on 1 page in the buffer. Setting this bit will trigger a VDMA request.
  [0] INIT rw — Initializes the bitstream DRM FSM. This bit can be set to start the bit stream DMA through SW programming only, without involving the ECD5 controller logic.
0x314 __ALL___DDR_BITSTRM_BASE_ADDR rw — DDR bitstream base address
  [31:0] ADDR — Base address of bit stream buffer in DDR
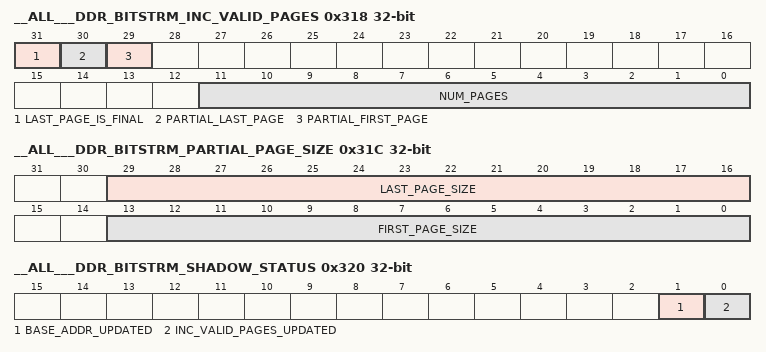
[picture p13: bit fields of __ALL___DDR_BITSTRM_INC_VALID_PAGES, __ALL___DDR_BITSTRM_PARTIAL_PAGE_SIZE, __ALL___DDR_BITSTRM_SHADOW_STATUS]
0x318 __ALL___DDR_BITSTRM_INC_VALID_PAGES — DDR bitstream incremental valid pages
  [31] LAST_PAGE_IS_FINAL rw — Flag indicating whether the last page in the current DDR data descriptor is the last in the DDR, i.e. no more data available in DDR after the last page in the current DDR data descriptor. The DRM's VDMA i/f will terminate after the transfer of the last page in the current descriptor, if this flag is set. Any descriptors already programmed after the current descriptor will remain unused.
  [30] PARTIAL_LAST_PAGE rw — Flag indicating whether the last page in the current DDR data descriptor is a partial page, i.e. it is not of the full page size. The size of the partial page is specified in DDR_BITSTRM_PARTIAL_PAGE_SIZE.LAST_PAGE_SIZE. Data transferred to/from the SL2 will be aligned to the top of the SL2 page, i.e. DDR_BITSTRM_PARTIAL_PAGE_SIZE.LAST_PAGE_SIZE amount of data will be transferred to/from the top of the current SL2 page.
  [29] PARTIAL_FIRST_PAGE rw — Flag indicating whether the first page in the current DDR data descriptor is a partial page, i.e. it is not of the full page size. The size of the partial page is specified in DDR_BITSTRM_PARTIAL_PAGE_SIZE.FIRST_PAGE_SIZE. Data transferred to/from the SL2 will be aligned to the bottom of the SL2 page, i.e. DDR_BITSTRM_PARTIAL_PAGE_SIZE.FIRST_PAGE_SIZE amount of data will be transferred to/from the bottom of the current SL2 page. Note : This field is ignored if NUM_PAGES == 1 and PARTIAL_LAST_PAGE == 1.
  [11:0] NUM_PAGES rw — Number of bitstream buffer pages that have been incrementally filled in DDR. Setting this field to 0 force terminates the DRM's VDMA i/f (forces DRM VDMA i/f FSM to IDLE state, clears the fields of DDR_BITSTRM_SHADOW_STATUS) after completion of all previous data transfers specified by any previous bit stream descriptor. If there are no data transfers pending, setting this field to 0 force terminates the DRM immediately. Additionally, setting this bit causes the DRM to signal the last page of the previous bitstream descriptor as last, to the SBC. Note : If PARTIAL_FIRST_PAGE == PARTIAL_LAST_PAGE == 1, then NUM_PAGES has to be greater than 2.
0x31C __ALL___DDR_BITSTRM_PARTIAL_PAGE_SIZE — DDR bitstream incremental valid pages
  [29:16] LAST_PAGE_SIZE rw — Indicates the size in bytes of the data in the last page. This field is valid only if the DDR_BITSTRM_INC_VALID_PAGES.PARTIAL_LAST_PAGE == 1
  [13:0] FIRST_PAGE_SIZE rw — Indicates the size in bytes of the data in the last page. This field is valid only if the DDR_BITSTRM_INC_VALID_PAGES.PARTIAL_FIRST_PAGE == 1
0x320 __ALL___DDR_BITSTRM_SHADOW_STATUS ro — DDR bitstream shadow status register
  [1] BASE_ADDR_UPDATED — Indicates if DDR_BITSTRM_BASE_ADDR contents have been updated 1 : DDR_BITSTRM_BASE_ADDR has been updated and contents have not yet been copied into the shadow register 0 : DDR_BITSTRM_BASE_ADDR has not been updated, or contents have already been copied into the shadow register; DDR_BITSTRM_BASE_ADDR can be written again
  [0] INC_VALID_PAGES_UPDATED — Indicates if DDR_BITSTRM_INC_VALID_PAGES contents have been updated 1 : DDR_BITSTRM_INC_VALID_PAGES has been updated and contents have not yet been copied into the shadow register 0 : DDR_BITSTRM_INC_VALID_PAGES has not been updated, or contents have already been copied into the shadow register; DDR_BITSTRM_INC_VALID_PAGES can be written again
